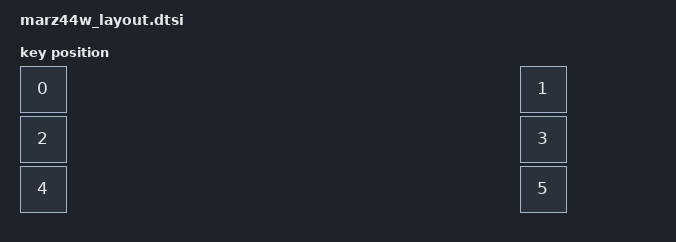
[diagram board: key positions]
// Generated by zkeymap: https://pypi.org/project/zkeymap/

#ifndef INCLUDED_MARZ44W_LAYOUT_H
#define INCLUDED_MARZ44W_LAYOUT_H

#include <physical_layouts.dtsi>

/ {
    marz_split_3x6_4: marz_split_3x6_4 {
        compatible = "zmk,physical-layout";
        display-name = "Corn like split but 3x6_4";
        keys //                       w    h       x       y     rot      rx      ry
            = <&key_physical_attrs  100  100       0    75.0       0       0       0>
            , <&key_physical_attrs  100  100     100    75.0       0       0       0>
            , <&key_physical_attrs  100  100     200    25.0       0       0       0>
            , <&key_physical_attrs  100  100     300       0       0       0       0>
            , <&key_physical_attrs  100  100     400    35.0       0       0       0>
            , <&key_physical_attrs  100  100     500    45.0       0       0       0>
            , <&key_physical_attrs  100  100    1100    45.0       0       0       0>
            , <&key_physical_attrs  100  100    1200    35.0       0       0       0>
            , <&key_physical_attrs  100  100    1300       0       0       0       0>
            , <&key_physical_attrs  100  100    1400    25.0       0       0       0>
            , <&key_physical_attrs  100  100    1500    75.0       0       0       0>
            , <&key_physical_attrs  100  100    1600    75.0       0       0       0>
            , <&key_physical_attrs  100  100       0   175.0       0       0       0>
            , <&key_physical_attrs  100  100     100   175.0       0       0       0>
            , <&key_physical_attrs  100  100     200   125.0       0       0       0>
            , <&key_physical_attrs  100  100     300     100       0       0       0>
            , <&key_physical_attrs  100  100     400   135.0       0       0       0>
            , <&key_physical_attrs  100  100     500   145.0       0       0       0>
            , <&key_physical_attrs  100  100    1100   145.0       0       0       0>
            , <&key_physical_attrs  100  100    1200   135.0       0       0       0>
            , <&key_physical_attrs  100  100    1300     100       0       0       0>
            , <&key_physical_attrs  100  100    1400   125.0       0       0       0>
            , <&key_physical_attrs  100  100    1500   175.0       0       0       0>
            , <&key_physical_attrs  100  100    1600   175.0       0       0       0>
            , <&key_physical_attrs  100  100       0   275.0       0       0       0>
            , <&key_physical_attrs  100  100     100   275.0       0       0       0>
            , <&key_physical_attrs  100  100     200   225.0       0       0       0>
            , <&key_physical_attrs  100  100     300     200       0       0       0>
            , <&key_physical_attrs  100  100     400   235.0       0       0       0>
            , <&key_physical_attrs  100  100     500   245.0       0       0       0>
            , <&key_physical_attrs  100  100    1100   245.0       0       0       0>
            , <&key_physical_attrs  100  100    1200   235.0       0       0       0>
            , <&key_physical_attrs  100  100    1300     200       0       0       0>
            , <&key_physical_attrs  100  100    1400   225.0       0       0       0>
            , <&key_physical_attrs  100  100    1500   275.0       0       0       0>
            , <&key_physical_attrs  100  100    1600   275.0       0       0       0>
            , <&key_physical_attrs  100  100   390.0   350.0    1000   390.0   350.0>
            , <&key_physical_attrs  100  100   500.0   370.0    1500   500.0   370.0>
            , <&key_physical_attrs  100  100   605.0   400.0    2000   605.0   400.0>
            , <&key_physical_attrs  100  100   710.0   440.0    2500   710.0   440.0>
            , <&key_physical_attrs  100  100   890.0   440.0 (-2500)   990.0   440.0>
            , <&key_physical_attrs  100  100   995.0   400.0 (-2000)  1095.0   400.0>
            , <&key_physical_attrs  100  100  1100.0   370.0 (-1500)  1200.0   370.0>
            , <&key_physical_attrs  100  100  1210.0   350.0 (-1000)  1310.0   350.0>
            ;
    };
};

#endif /* INCLUDED_MARZ44W_LAYOUT_H */
